# D2522AA register map
Vendor: Dialog; Series: D2522AA; File version: 1.2
CPU: CM0 r1p0, little endian, MPU, FPU, 3 interrupt priority bits
Registers are 32-bit, read-write, reset 0x0 unless marked. A register's access mark holds for its fields unless they carry their own. Offsets are from the block's base; [hi:lo] are bit positions; {n}, {i} and the like mark numbered series.

## DEM — DEM registers
Base 0x40021000
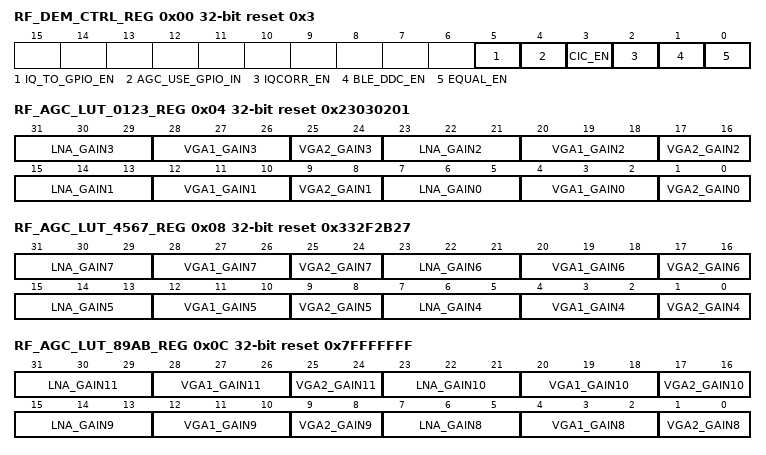
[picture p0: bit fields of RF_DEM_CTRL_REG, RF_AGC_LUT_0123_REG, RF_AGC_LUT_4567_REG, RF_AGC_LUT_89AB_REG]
0x00 RF_DEM_CTRL_REG reset 0x3
  [5] IQ_TO_GPIO_EN — Enable the IQ data output for exposed radio mode.
  [4] AGC_USE_GPIO_IN — Select to use the GPIO input as AGC setting. To be used with FPGA platform
  [3] CIC_EN — Enable the CIC filter in the decimator.
  [2] IQCORR_EN — Enable the IQ mismatch correction The correction coefficients are define in the RF_DEM_IQCORRECT_REG register
  [1] BLE_DDC_EN — Enable the digital conversion in BLE mode
  [0] EQUAL_EN — Enable the equalizer in the demodulator
0x04 RF_AGC_LUT_0123_REG reset 0x23030201 (reset mask 0x7FFFFFFF)
  [31:29] LNA_GAIN3 — LNA gain setting while in AGC setting 3
  [8n+4:8n+2] VGA1_GAIN{n} (n=0..3) — VGA1 gain setting while in AGC setting {n}
  [8n+1:8n] VGA2_GAIN{n} (n=0..3) — VGA2 gain setting while in AGC setting {n}
  [23:21] LNA_GAIN2 — LNA gain setting while in AGC setting 2
  [15:13] LNA_GAIN1 — LNA gain setting while in AGC setting 0
  [7:5] LNA_GAIN0 — LNA gain setting while in AGC setting 0
0x08 RF_AGC_LUT_4567_REG reset 0x332F2B27 (reset mask 0x7FFFFFFF)
  [8n-25:8n-27] LNA_GAIN{n} (n=4..7) — LNA gain setting while in AGC setting {n}
  [8n-28:8n-30] VGA1_GAIN{n} (n=4..7) — VGA1 gain setting while in AGC setting {n}
  [8n-31:8n-32] VGA2_GAIN{n} (n=4..7) — VGA2 gain setting while in AGC setting {n}
0x0C RF_AGC_LUT_89AB_REG reset 0x7FFFFFFF (reset mask 0x7FFFFFFF)
  [8n-57:8n-59] LNA_GAIN{n} (n=8..11) — LNA gain setting while in AGC setting {n}
  [28:26] VGA1_GAIN11 — VGA1 gain setting while in AGC setting 11
  [8n-63:8n-64] VGA2_GAIN{n} (n=8..11) — VGA2 gain setting while in AGC setting {n}
  [20:18] VGA1_GAIN10 — VGA1 Gain setting while in AGC setting 10
  [12:10] VGA1_GAIN9 — VGA1 gain setting while in AGC setting 9
  [4:2] VGA1_GAIN8 — VGA1 gain setting while in AGC setting 8
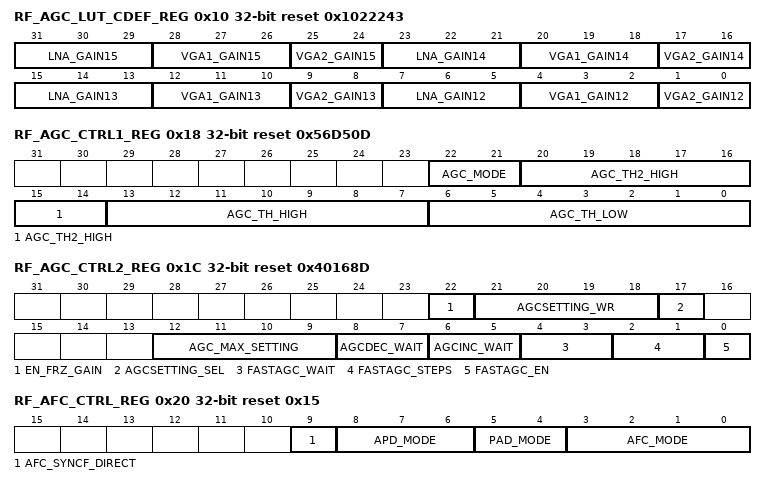
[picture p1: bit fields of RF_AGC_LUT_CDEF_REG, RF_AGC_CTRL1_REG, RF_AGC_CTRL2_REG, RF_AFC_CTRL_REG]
0x10 RF_AGC_LUT_CDEF_REG reset 0x1022243 (reset mask 0x7FFFFFFF)
  [8n-89:8n-91] LNA_GAIN{n} (n=12..15) — LNA gain setting while in AGC setting {n}
  [28:26] VGA1_GAIN15 — VGA1 gain setting while in AGC setting 15
  [8n-95:8n-96] VGA2_GAIN{n} (n=12..15) — VGA2 gain setting while in AGC setting {n}
  [20:18] VGA1_GAIN14 — VGA1 Gain setting while in AGC setting 14
  [12:10] VGA1_GAIN13 — VGA1 gain setting while in AGC setting 13
  [4:2] VGA1_GAIN12 — VGA1 gain setting while in AGC setting 12
0x18 RF_AGC_CTRL1_REG reset 0x56D50D
  [22:21] AGC_MODE — Choose the method to use for AGC evaluation Description TBD
  [20:14] AGC_TH2_HIGH — AGC treshhold for FASTAGC mode... switch up number of steps defined by FASTAGC_STEPS
  [13:7] AGC_TH_HIGH — AGC hysteresis high threshold (switch up one AGC_SETTING_R step when exceeding this level)
  [6:0] AGC_TH_LOW — AGC hysteresis low threshold (switch down one AGC_SETTING_R step when dropping below this level)
0x1C RF_AGC_CTRL2_REG reset 0x40168D
  [22] EN_FRZ_GAIN — '0': AGC always active'1': Freeze gain after Access Address detection
  [21:18] AGCSETTING_WR — Fixed AGC setting to be used to configure LNA, VGA1 and VGA2 when AGCSETTING_SEL = 1 0: Highest gain as configured in RF_AGC_LUT_01_REG 1: Lower gain as configured in RF_AGC_LUT_01_REG 2: Still lower gain as configured in RF_AGC_LUT_23_REG ... 9-F: Lowest gain as configured in RF_AGC_LUT_89_REG
  [17] AGCSETTING_SEL — LNA, VGA1 and VGA2 gains '0': controlled by AGC'1': provided manually through AGCSETTING_WR
  [12:9] AGC_MAX_SETTING — Maximum AGC setting used from AGC LUT
  [8:7] AGCDEC_WAIT — Wait time for settling after a single AGC step decrease (increasing gain) 0x0 - 1us 0x1 - 2us 0x2 - 3us 0x3 - 4us
  [6:5] AGCINC_WAIT — Wait time for settling after a single AGC step increase (decreasing gain) 0x0 - 1us 0x1 - 2us 0x2 - 3us 0x3 - 4us
  [4:3] FASTAGC_WAIT — Wait time for signal settling after fast AGC toggling 0x0 - 1us 0x1 - 2us 0x2 - 3us 0x3 - 4us
  [2:1] FASTAGC_STEPS — Define the number of 6dB steps that is used when the RSSI level is larger than AGC_TH2_HIGH 0x0 - 1 step 0x1 - 2 steps 0x2 - 3 steps 0x3 - 4 steps
  [0] FASTAGC_EN — Allow the AGC to decrease the gain by multiple steps of 6dB
0x20 RF_AFC_CTRL_REG reset 0x15
  [9] AFC_SYNCF_DIRECT — Allow the AFC state to directly transit from IDLE or PREAMBLE detection state to LOCKED state
  [8:6] APD_MODE — Select the mode in the APD FSM: xx1: Enable the transition from the ADDRESSDETECTION state to the IDLE state when the signal detection is low x1x: Enable the reset of the AFC filter when the FSM is in the IDLE state 1xx: Enable the time out in the PREAMBLEDETECTION state. The FSM returns to the IDLE state after the time out.
  [5:4] PAD_MODE — The PAD mode in BLE mode 00: No limits 01: Wrapping 10: Saturate to zero 11: 580 legacy mode
  [3:0] AFC_MODE — Choose the method to use for AFC tracking during the slot Description TBD
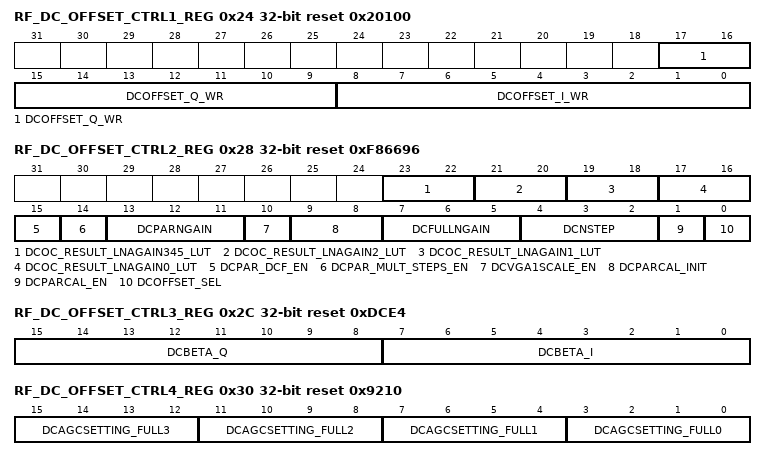
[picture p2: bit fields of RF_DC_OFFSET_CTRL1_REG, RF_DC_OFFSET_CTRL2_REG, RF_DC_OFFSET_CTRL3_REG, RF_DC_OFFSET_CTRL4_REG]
0x24 RF_DC_OFFSET_CTRL1_REG reset 0x20100
  [17:9] DCOFFSET_Q_WR — DC offset compensation value in Q channel valid when DCOFFSET_SEL = 1
  [8:0] DCOFFSET_I_WR — DC offset compensation value in I channel valid when DCOFFSET_SEL = 1
0x28 RF_DC_OFFSET_CTRL2_REG reset 0xF86696
  [23:22] DCOC_RESULT_LNAGAIN345_LUT — DCoffset result used for LNA gain settings 3 4 and 5.
  [21:20] DCOC_RESULT_LNAGAIN2_LUT — DCoffset result used for LNA gain setting 2
  [19:18] DCOC_RESULT_LNAGAIN1_LUT — DCoffset result used for LNA gain setting 1
  [17:16] DCOC_RESULT_LNAGAIN0_LUT — DCoffset result used for LNA gain setting 0
  [15] DCPAR_DCF_EN — Use a DCF to start the partial DC offset calibration.
  [14] DCPAR_MULT_STEPS_EN — Enable the partial DCOC calibration with multiple gain settings. When not set, the partial calibration is the same as in 680BA.
  [13:11] DCPARNGAIN — Number of gain settings for the partial DC offset calibration
  [10] DCVGA1SCALE_EN — Enable the DC offset scaling with the VGA1 gain
  [9:8] DCPARCAL_INIT — Select the inital value used for the partial DC offset calibration. 0: The DC offset from the previous packet 1: The DC offset found with the full DC offset calibration 2: Start from the mid value.
  [7:5] DCFULLNGAIN — Number of gain settings for the full DC offset calibration
  [4:2] DCNSTEP — Number of the steps per.gain setting for the full or partial DC offset calibrations
  [1] DCPARCAL_EN — Enable flag for the partial DC offset calibration The calbration is executed when the demodulator is enabled. When the bit DCPAR_DCF_EN is set, the enabling is started by the DCF.
  [0] DCOFFSET_SEL — '0': Normal operation '1': Use the manual DC offset compensation values from RF_DC_OFFSET_CTRL1_REG
0x2C RF_DC_OFFSET_CTRL3_REG reset 0xDCE4
  [15:8] DCBETA_Q — Quadrature feedback gain for the DC offset calibration
  [7:0] DCBETA_I — Inphase feedback gain for the DC offset calibration
0x30 RF_DC_OFFSET_CTRL4_REG reset 0x9210
  [15:12] DCAGCSETTING_FULL3 — AGC setting for forth last the gain step for the full DC offset calibration
  [11:8] DCAGCSETTING_FULL2 — AGC setting for third last the gain step for the full DC offset calibration
  [7:4] DCAGCSETTING_FULL1 — AGC setting for second last the gain step for the full DC offset calibration
  [3:0] DCAGCSETTING_FULL0 — AGC setting for last the gain step for the full DC offset calibration
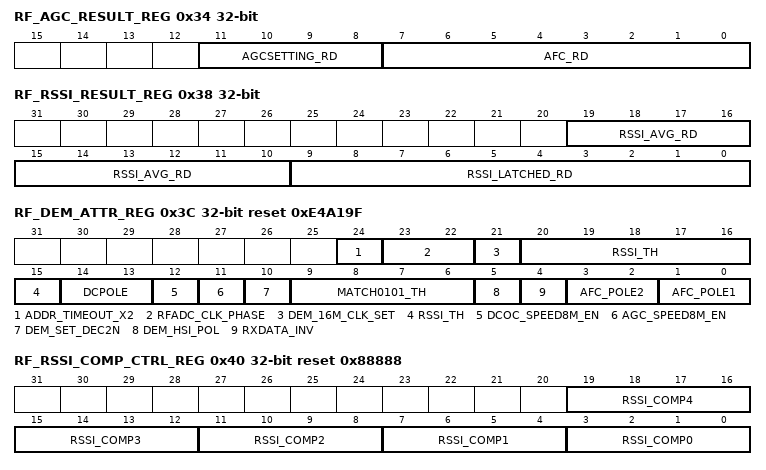
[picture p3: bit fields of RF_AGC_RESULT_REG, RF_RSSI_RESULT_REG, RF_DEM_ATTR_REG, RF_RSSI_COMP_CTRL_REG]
0x34 RF_AGC_RESULT_REG
  [11:8] AGCSETTING_RD ro — AGC setting as automatically selected in receive mode to configure LNA, VGA1 and VGA2 0: Highest gain as configured in RF_AGC_LUT_01_REG 1: Lower gain as configured in RF_AGC_LUT_01_REG 2: Still lower gain as configured in RF_AGC_LUT_23_REG ... 9-F: Lowest gain as configured in RF_AGC_LUT_89_REG
  [7:0] AFC_RD ro — Frequency offset estimation (in 2s complement) with a resolution of approximately 5 kHz.
0x38 RF_RSSI_RESULT_REG
  [19:10] RSSI_AVG_RD ro — RSSI value measured in averaging mode in continuous RX mode (used for LNA selectivity calibration)
  [9:0] RSSI_LATCHED_RD ro — Averaged RSSI value latched with the Sync Found Pulse. Value is resetted when the demodulator is started and when stopped.
0x3C RF_DEM_ATTR_REG reset 0xE4A19F
  [24] ADDR_TIMEOUT_X2 — Program the Address Time Out when AFC is in MAC ADDRESS correlation state 0x0 - short time (32us in 2Mbit mode and 64us in 1Mbit mode) 0x1 - long time (64us in 2Mbit mode and 128us in 1Mbit mode)
  [23:22] RFADC_CLK_PHASE — Select the phase of the RFADC clock
  [21] DEM_16M_CLK_SET — Sets the Demodulator clock speed. Automatically the RFADC speed is adjusted as well.
  [20:15] RSSI_TH — RSSI threshold for the packet detection
  [14:13] DCPOLE — Set the frequency of the DC offset highpass filter. The frequency is different when the demodulator is used with 8MHz or 16MHz clock. For 8MHz clock: 0x0 - 100kHz 0x1 - 50kHz 0x2 - 150kHz 0x3 - N/A
  [12] DCOC_SPEED8M_EN — Set the preferred Clock Speed for the DC Offset Block
  [11] AGC_SPEED8M_EN — Set the preferred clock speed for the AGC block
  [10] DEM_SET_DEC2N — Bit to select of the deimate by 2 is enabled. 0 - Decimation by 2 is enabled, use for 1Mbit mode with 16MHz clock 1 - Decimation by 2 disabled, use for 2Mbit mode with 16MHz clock or 1Mbit mode with 8MHz clock
  [9:6] MATCH0101_TH — Threshold for the 0101 pattern matching
  [5] DEM_HSI_POL — Invert "frequency" polarity of the demodulator
  [4] RXDATA_INV — '0': Normal operation '1': Invert the polarity of the received bits
  [3:2] AFC_POLE2 — Set the frequency of the AFC pole (Highpass filter) that is used before and after preamble detection. The absolute frequency is different for 1Mbit and 2Mbit mode. 3dB cut off frequency in 1Mbit mode. 0 - NA 1 - 78Hz 2 - 156Hz 3 - 311Hz In 2Mbit mode, the frequency doubles.
  [1:0] AFC_POLE1 — Set the frequency of the AFC pole (Highpass filter) that is used during preamble detection. The absolute frequency is different for 1Mbit and 2Mbit mode. 3dB cut off frequency in 1Mbit mode. 0 - NA 1 - 1.3kHz 2 - 2.5kHz 3 - 5.1kHz In 2Mbit mode, the frequency doubles.
0x40 RF_RSSI_COMP_CTRL_REG reset 0x88888
  [19:16] RSSI_COMP4 — RSSI compensation value for LNA gain setting 3 Coding identical to RSSI_COMP0
  [15:12] RSSI_COMP3 — RSSI compensation value for LNA gain setting 3 Coding identical to RSSI_COMP0
  [11:8] RSSI_COMP2 — RSSI compensation value for LNA gain setting 2 Coding identical to RSSI_COMP0
  [7:4] RSSI_COMP1 — RSSI compensation value for LNA gain setting 1 '0x0': -8 '0x1': -7 '0x2': -6 '0x3': -5 '0x4': -4 '0x5': -3 '0x6': -2 '0x7': -1 '0x8': 0 (reset) '0x9': 1 '0xA': 2 '0xB': 3 '0xC': 4 '0xD': 5 '0xE': 6 '0xF': 7
  [3:0] RSSI_COMP0 — RSSI compensation value for LNA gain setting 00 '0x0': -8 '0x1': -7 '0x2': -6 '0x3': -5 '0x4': -4 '0x5': -3 '0x6': -2 '0x7': -1 '0x8': 0 (reset) '0x9': 1 '0xA': 2 '0xB': 3 '0xC': 4 '0xD': 5 '0xE': 6 '0xF': 7
0x44 RF_DEM_TESTMODE_REG
  [9:0] DEM_TESTMODE — Defines the demodulator test mode DEM_TESTMODE[3:0] selects the data mapped on the testbus (see demodulator documentation for details. The upper and lower 16-bits test data are swapped when DEM_TESTMODE[4] is set. The lower 16-bits are assigned to the test bus when DEM_TESTMODE[5] is set. The input test bus is copied when DEM_TESTMODE[6] is reset. The upper 16-bits are assigned to the test bus when DEM_TESTMODE[6] is set. The input test bus is copied with DEM_TESTMODE[7] is reset. The trigger is slected with DEM_TESTMODE[8:7] 00: dem_en 01: Signal detected 10: Set with the rising edge of DEM_EN and reset with the rising edge of SYNC_FOUND_P 11: Set with the rising edge of SYNC_FOUND_P and reset with the falling edge of DEM_EN DEM_TESTMODE[9] is reserved
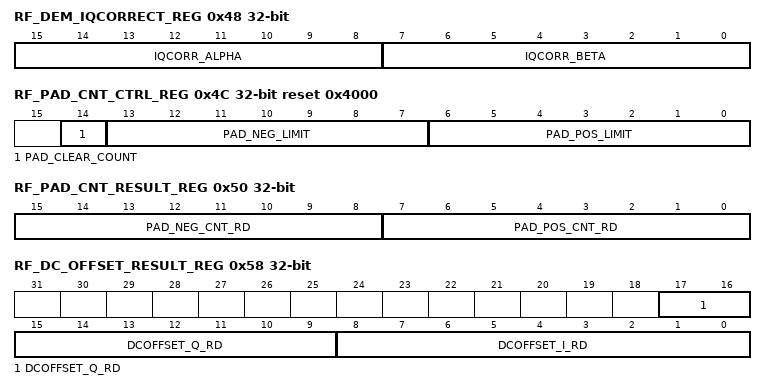
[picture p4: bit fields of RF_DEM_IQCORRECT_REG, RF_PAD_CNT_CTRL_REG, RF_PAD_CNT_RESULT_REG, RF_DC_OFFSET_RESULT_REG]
0x48 RF_DEM_IQCORRECT_REG
  [15:8] IQCORR_ALPHA, [7:0] IQCORR_BETA
0x4C RF_PAD_CNT_CTRL_REG reset 0x4000
  [14] PAD_CLEAR_COUNT, [13:7] PAD_NEG_LIMIT, [6:0] PAD_POS_LIMIT
0x50 RF_PAD_CNT_RESULT_REG
  [15:8] PAD_NEG_CNT_RD ro, [7:0] PAD_POS_CNT_RD ro
0x58 RF_DC_OFFSET_RESULT_REG — Must be Retained
  [17:9] DCOFFSET_Q_RD ro — DC offset compensation value in Q channel valid when DCOFFSET_SEL = 0
  [8:0] DCOFFSET_I_RD ro — DC offset compensation value in I channel valid when DCOFFSET_SEL = 0.
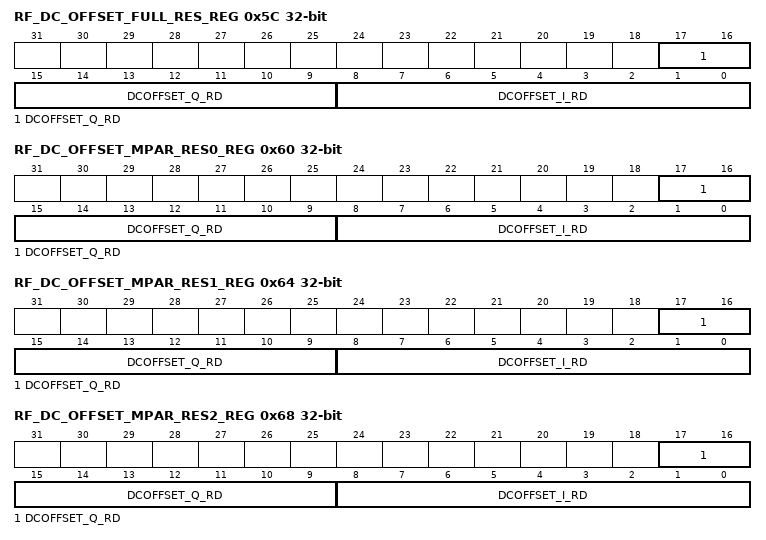
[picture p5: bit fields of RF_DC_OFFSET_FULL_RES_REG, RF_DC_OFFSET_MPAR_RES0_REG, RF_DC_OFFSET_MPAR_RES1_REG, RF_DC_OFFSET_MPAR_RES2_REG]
0x5C RF_DC_OFFSET_FULL_RES_REG — Must be Retained
  [17:9] DCOFFSET_Q_RD ro — Stored DC offset FULL calibration result value of the Q channel.
  [8:0] DCOFFSET_I_RD ro — Stored DC offset FULL calibration result value of the Q channel.
0x60 RF_DC_OFFSET_MPAR_RES0_REG
  [17:9] DCOFFSET_Q_RD ro — DC offset calibration result value of the last step of the multiple partial calibration. (Q channel)
  [8:0] DCOFFSET_I_RD ro — DC offset calibration result value of the last step of the multiple partial calibration. (I channel)
0x64 RF_DC_OFFSET_MPAR_RES1_REG
  [17:9] DCOFFSET_Q_RD ro — DC offset calibration result value of the (last step -1) of the multiple partial calibration. (Q channel)
  [8:0] DCOFFSET_I_RD ro — DC offset calibration result value of the (last step -1) of the multiple partial calibration. (I channel)
0x68 RF_DC_OFFSET_MPAR_RES2_REG
  [17:9] DCOFFSET_Q_RD ro — DC offset calibration result value of the (last step -2) of the multiple partial calibration. (Q channel)
  [8:0] DCOFFSET_I_RD ro — DC offset calibration result value of the (last step-2) of the multiple partial calibration. (I channel)
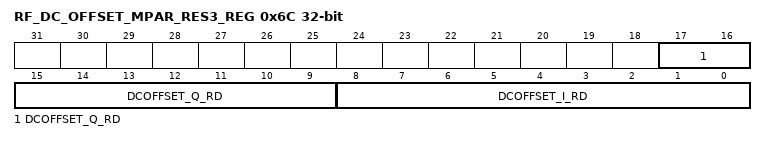
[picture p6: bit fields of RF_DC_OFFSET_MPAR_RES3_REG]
0x6C RF_DC_OFFSET_MPAR_RES3_REG
  [17:9] DCOFFSET_Q_RD ro — DC offset calibration result value of the (last step -3) of the multiple partial calibration. (Q channel)
  [8:0] DCOFFSET_I_RD ro — DC offset calibration result value of the (last step-3) of the multiple partial calibration. (I channel)
